# STM32N645 register map
File version: 1.0
CPU: CM55 r0p1, little endian, no MPU, FPU, vendor SysTick, 8 interrupt priority bits
Registers are 32-bit, read-write, reset 0x0 unless marked. A register's access mark holds for its fields unless they carry their own. Offsets are from the block's base; [hi:lo] are bit positions; lines under a group give offsets from that group; {n}, {i} and the like mark numbered series.

## DCMI — Digital camera interface
Base 0x48028400
Same registers: DCMI_S 0x58028400
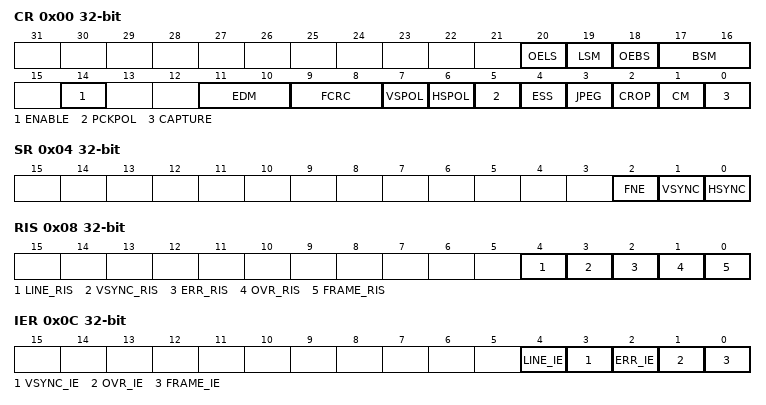
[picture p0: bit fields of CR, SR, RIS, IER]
0x00 CR — DCMI control register
  [20] OELS — Odd/Even Line Select (Line Select Start)
  [19] LSM — Line Select mode
  [18] OEBS — Odd/Even Byte Select (Byte Select Start)
  [17:16] BSM — Byte Select mode
  [14] ENABLE — DCMI enable
  [11:10] EDM — Extended data mode
  [9:8] FCRC — Frame capture rate control
  [7] VSPOL — Vertical synchronization polarity
  [6] HSPOL — Horizontal synchronization polarity
  [5] PCKPOL — Pixel clock polarity
  [4] ESS — Embedded synchronization select
  [3] JPEG — JPEG format
  [2] CROP — Crop feature
  [1] CM — Capture mode
  [0] CAPTURE — Capture enable
0x04 SR ro — DCMI status register
  [2] FNE — FIFO not empty
  [1] VSYNC — Vertical synchronization
  [0] HSYNC — Horizontal synchronization
0x08 RIS ro — DCMI raw interrupt status register
  [4] LINE_RIS — Line raw interrupt status
  [3] VSYNC_RIS — DCMI_VSYNC raw interrupt status
  [2] ERR_RIS — Synchronization error raw interrupt status
  [1] OVR_RIS — Overrun raw interrupt status
  [0] FRAME_RIS — Capture complete raw interrupt status
0x0C IER — DCMI interrupt enable register
  [4] LINE_IE — Line interrupt enable
  [3] VSYNC_IE — DCMI_VSYNC interrupt enable
  [2] ERR_IE — Synchronization error interrupt enable
  [1] OVR_IE — Overrun interrupt enable
  [0] FRAME_IE — Capture complete interrupt enable
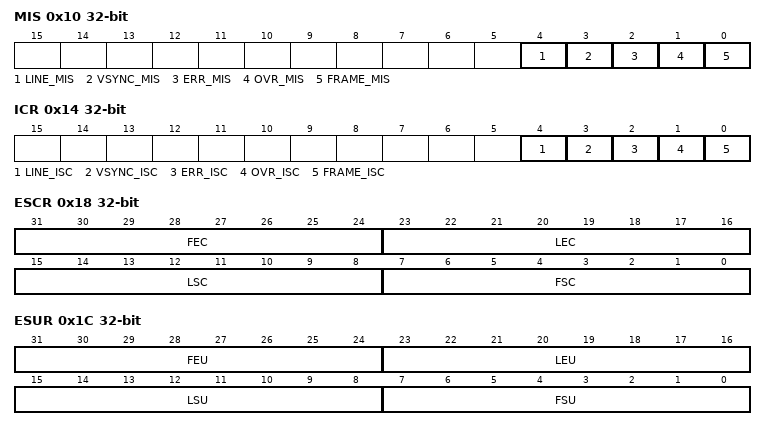
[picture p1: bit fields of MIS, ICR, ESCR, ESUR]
0x10 MIS ro — DCMI masked interrupt status register
  [4] LINE_MIS — Line masked interrupt status
  [3] VSYNC_MIS — VSYNC masked interrupt status
  [2] ERR_MIS — Synchronization error masked interrupt status
  [1] OVR_MIS — Overrun masked interrupt status
  [0] FRAME_MIS — Capture complete masked interrupt status
0x14 ICR wo — DCMI interrupt clear register
  [4] LINE_ISC — line interrupt status clear
  [3] VSYNC_ISC — Vertical Synchronization interrupt status clear
  [2] ERR_ISC — Synchronization error interrupt status clear
  [1] OVR_ISC — Overrun interrupt status clear
  [0] FRAME_ISC — Capture complete interrupt status clear
0x18 ESCR — DCMI embedded synchronization code register
  [31:24] FEC — Frame end delimiter code
  [23:16] LEC — Line end delimiter code
  [15:8] LSC — Line start delimiter code
  [7:0] FSC — Frame start delimiter code
0x1C ESUR — DCMI embedded synchronization unmask register
  [31:24] FEU — Frame end delimiter unmask
  [23:16] LEU — Line end delimiter unmask
  [15:8] LSU — Line start delimiter unmask
  [7:0] FSU — Frame start delimiter unmask
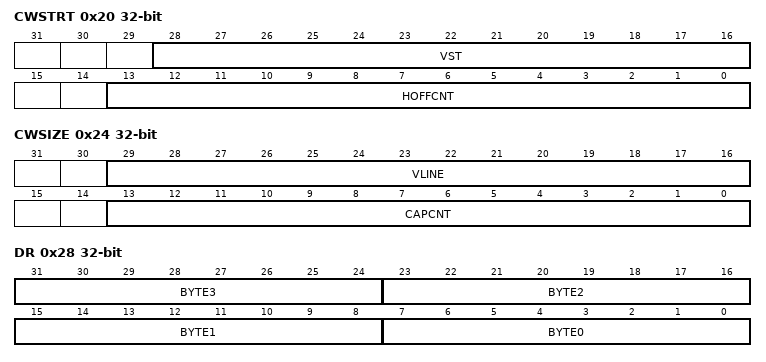
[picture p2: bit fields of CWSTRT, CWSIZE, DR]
0x20 CWSTRT — DCMI crop window start
  [28:16] VST — Vertical start line count
  [13:0] HOFFCNT — Horizontal offset count
0x24 CWSIZE — DCMI crop window size
  [29:16] VLINE — Vertical line count
  [13:0] CAPCNT — Capture count
0x28 DR ro — DCMI data register
  [8n+7:8n] BYTE{n} (n=0..3) — Data byte {n}

## DLYBSD — DLYBSD address block description
Base 0x48028000
Same registers: DLYBSD2 0x48026C00, DLYBSD2_S 0x58026C00, DLYBSD_S 0x58028000
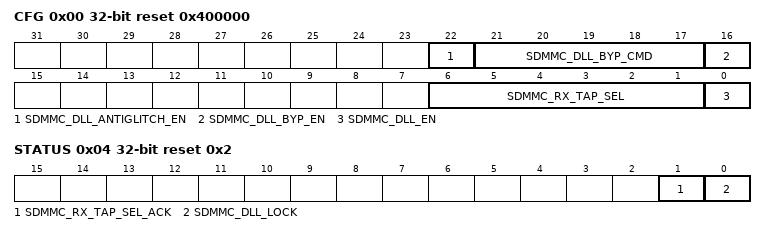
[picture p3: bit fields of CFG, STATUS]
0x00 CFG reset 0x400000 — Delay block SDMMC DLL configuration
  [22] SDMMC_DLL_ANTIGLITCH_EN — Antiglitch logic enabled when 1
  [21:17] SDMMC_DLL_BYP_CMD — Bypass command
  [16] SDMMC_DLL_BYP_EN — DLL configuration
  [6:1] SDMMC_RX_TAP_SEL — selection of RX delay
  [0] SDMMC_DLL_EN — DLL enable
0x04 STATUS reset 0x2 — Delay block SDMMC DLL status
  [1] SDMMC_RX_TAP_SEL_ACK — SDMMC RX delay selection acknowledge
  [0] SDMMC_DLL_LOCK

## GFXMMU — Chrom-GRC
Base 0x48030000
Same registers: GFXMMU_S 0x58030000
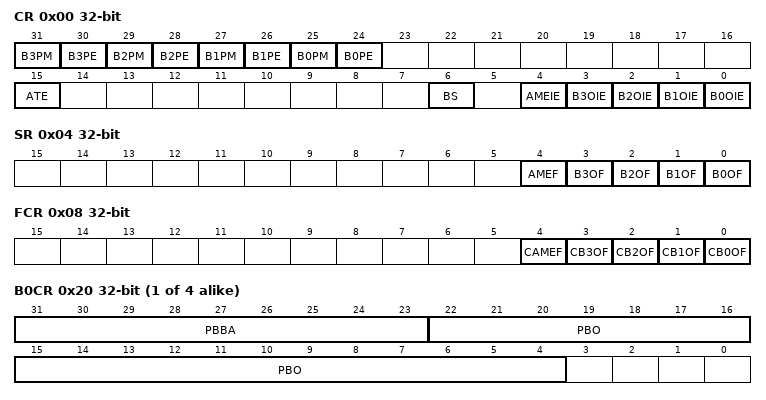
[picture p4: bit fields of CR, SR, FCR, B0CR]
0x00 CR — GFXMMU configuration register
  [2n+25] B{n}PM (n=0..3) — Buffer {n} packing mode
  [2n+24] B{n}PE (n=0..3) — Buffer {n} packing enable
  [15] ATE — Address translation enable
  [6] BS — Block size
  [4] AMEIE — AXI master error interrupt enable
  [n] B{n}OIE (n=0..3) — Buffer {n} overflow interrupt enable
0x04 SR ro — GFXMMU status register
  [4] AMEF — AXI master error flag
  [n] B{n}OF (n=0..3) — Buffer {n} overflow flag
0x08 FCR — GFXMMU flag clear register
  [4] CAMEF — Clear AXI master error flag
  [n] CB{n}OF (n=0..3) — Clear buffer {n} overflow flag
0x10 DVR — GFXMMU default value register
  [31:0] DV — Default value
0x14 DAR — GFXMMU default alpha register
  [7:0] DA — Default alpha
{0x20+4i} B{i}CR (i=0..3) — GFXMMU buffer {i} configuration register
  [31:23] PBBA — Physical buffer base address
  [22:4] PBO — Physical buffer offset
{0x1000+8i} LUT{i} (i=0..1023) group — Cluster LUT{i}, containing LUT*L, LUT*H
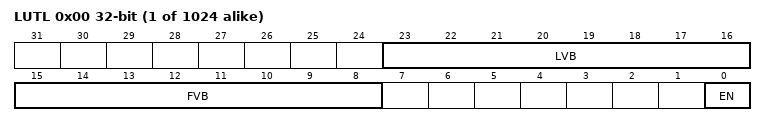
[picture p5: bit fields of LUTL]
  0x00 LUTL — Graphic MMU LUT entry x low
    [23:16] LVB — Last valid block
    [15:8] FVB — First valid block
    [0] EN — Enable
  0x04 LUTH — Graphic MMU LUT entry x high
    [17:0] LO — Line offset
